VERSION ""

NS_ :

BS_:

BU_:

BO_ 177 sampleFrame2: 4 Vector__XXX
 SG_ wheelspeed : 16|16@1+ (0.2,0) [0|13107] "rpm" Vector__XXX

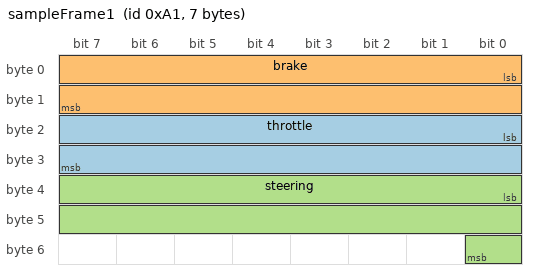
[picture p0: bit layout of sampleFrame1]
BO_ 161 sampleFrame1: 7 Vector__XXX
 SG_ throttle : 16|16@1+ (0.0001,0) [0|1] "%" Vector__XXX
 SG_ brake : 0|16@1+ (0.0001,0) [0|1] "%" Vector__XXX
 SG_ steering : 32|17@1- (0.01,0) [-655.36|655.35] "degree" Vector__XXX

BA_DEF_  "BusType" STRING ;
BA_DEF_DEF_  "BusType" "CAN";
